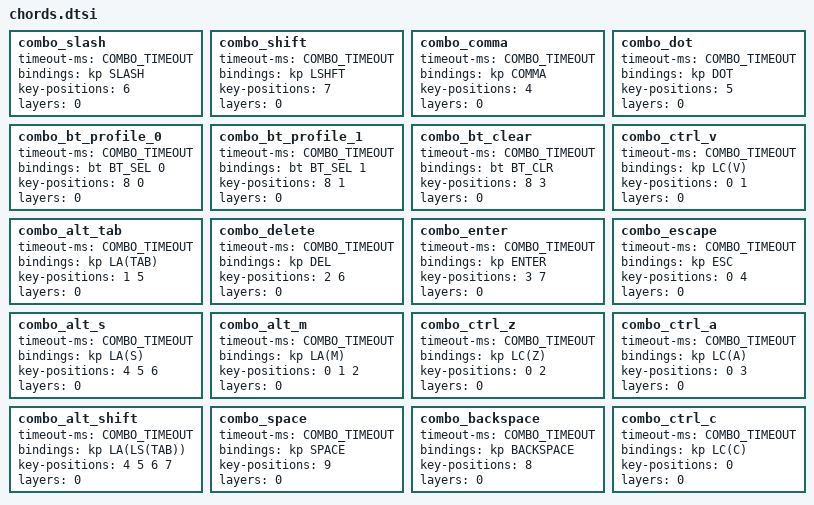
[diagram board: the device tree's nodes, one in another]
/*
 * PNCATEHO (RISATENO) - Custom Keymap Configuration
 * Left hand only (10 keys)
 * Custom macros and combinations
 * 
 * ЛОГИЧЕСКИЕ ПОЗИЦИИ (из matrix_transform):
 * TLP=0, TLR=1, TLM=2, TLI=3   (верхний ряд)
 * BLP=4, BLR=5, BLM=6, BLI=7   (нижний ряд)
 * LOT=8, LIT=9                 (большие пальцы)
 */

// ===== SINGLE KEY COMBOS (одно нажатие) =====

// / (slash) на позиции BLM (6)
combo_slash {
    timeout-ms = <COMBO_TIMEOUT>;
    bindings = <&kp SLASH>;
    key-positions = <6>;
    layers = <0>;
};

// Shift на позиции BLI (7)
combo_shift {
    timeout-ms = <COMBO_TIMEOUT>;
    bindings = <&kp LSHFT>;
    key-positions = <7>;
    layers = <0>;
};

// Запятая на позиции BLP (4)
combo_comma {
    timeout-ms = <COMBO_TIMEOUT>;
    bindings = <&kp COMMA>;
    key-positions = <4>;
    layers = <0>;
};

// Точка на позиции BLR (5)
combo_dot {
    timeout-ms = <COMBO_TIMEOUT>;
    bindings = <&kp DOT>;
    key-positions = <5>;
    layers = <0>;
};

// ===== DOUBLE KEY COMBOS (две позиции) =====

combo_bt_profile_0 {
    timeout-ms = <COMBO_TIMEOUT>;
    bindings = <&bt BT_SEL 0>;
    key-positions = <8 0>;
    layers = <0>;
};

combo_bt_profile_1 {
    timeout-ms = <COMBO_TIMEOUT>;
    bindings = <&bt BT_SEL 1>;
    key-positions = <8 1>;
    layers = <0>;
};

combo_bt_clear {
    timeout-ms = <COMBO_TIMEOUT>;
    bindings = <&bt BT_CLR>;
    key-positions = <8 3>;
    layers = <0>;
};

// TLP + TLR = Ctrl+V (позиции 0+1)
combo_ctrl_v {
    timeout-ms = <COMBO_TIMEOUT>;
    bindings = <&kp LC(V)>;
    key-positions = <0 1>;
    layers = <0>;
};

// Alt+Tab = TLR + BLR (позиции 1+5)
combo_alt_tab {
    timeout-ms = <COMBO_TIMEOUT>;
    bindings = <&kp LA(TAB)>;
    key-positions = <1 5>;
    layers = <0>;
};

// Delete = TLM + BLM (позиции 2+6)
combo_delete {
    timeout-ms = <COMBO_TIMEOUT>;
    bindings = <&kp DEL>;
    key-positions = <2 6>;
    layers = <0>;
};

// Enter = TLI + BLI (позиции 3+7)
combo_enter {
    timeout-ms = <COMBO_TIMEOUT>;
    bindings = <&kp ENTER>;
    key-positions = <3 7>;
    layers = <0>;
};

// Esc = TLP + BLP (позиции 0+4)
combo_escape {
    timeout-ms = <COMBO_TIMEOUT>;
    bindings = <&kp ESC>;
    key-positions = <0 4>;
    layers = <0>;
};

// Alt+S = BLP + BLR + BLM (позиции 4+5+6)
combo_alt_s {
    timeout-ms = <COMBO_TIMEOUT>;
    bindings = <&kp LA(S)>;
    key-positions = <4 5 6>;
    layers = <0>;
};

// ===== TRIPLE KEY COMBOS (три позиции) =====

// Alt+M = TLP + TLR + TLM (позиции 0+1+2)
combo_alt_m {
    timeout-ms = <COMBO_TIMEOUT>;
    bindings = <&kp LA(M)>;
    key-positions = <0 1 2>;
    layers = <0>;
};

// Ctrl+Z = TLP + TLM (позиции 0+3)
combo_ctrl_z {
    timeout-ms = <COMBO_TIMEOUT>;
    bindings = <&kp LC(Z)>;
    key-positions = <0 2>;
    layers = <0>;
};

// Ctrl+A = TLP + TLI (позиции 0+3)
combo_ctrl_a {
    timeout-ms = <COMBO_TIMEOUT>;
    bindings = <&kp LC(A)>;
    key-positions = <0 3>;
    layers = <0>;
};

// ===== QUAD KEY COMBOS (четыре позиции) =====

// Alt+Shift = BLP + BLR + BLM + BLI (позиции 4+5+6+7)
combo_alt_shift {
    timeout-ms = <COMBO_TIMEOUT>;
    bindings = <&kp LA(LS(TAB))>;
    key-positions = <4 5 6 7>;
    layers = <0>;
};


// ===== SPACE и BACKSPACE (на пальцы) =====

// Space на LIT (палец 9)
combo_space {
    timeout-ms = <COMBO_TIMEOUT>;
    bindings = <&kp SPACE>;
    key-positions = <9>;
    layers = <0>;
};

// Backspace на LOT (палец 8)
combo_backspace {
    timeout-ms = <COMBO_TIMEOUT>;
    bindings = <&kp BACKSPACE>;
    key-positions = <8>;
    layers = <0>;
};

// ===== PRIMARY COMBO (самая частая) =====

// TLP (позиция 0) = Ctrl+C
combo_ctrl_c {
    timeout-ms = <COMBO_TIMEOUT>;
    bindings = <&kp LC(C)>;
    key-positions = <0>;
    layers = <0>;
};
